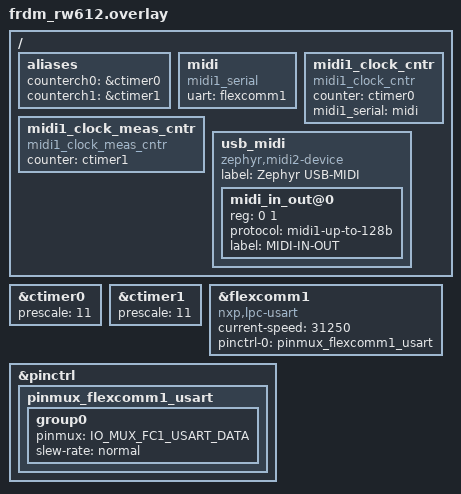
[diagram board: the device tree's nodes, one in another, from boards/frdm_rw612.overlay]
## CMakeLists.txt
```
# SPDX-License-Identifier: Apache-2.0

cmake_minimum_required(VERSION 3.20.0)

find_package(Zephyr REQUIRED HINTS $ENV{ZEPHYR_BASE})
project(chord_display)

target_sources(app PRIVATE 
    src/main.c
    src/chord_detector.c
    src/display.c
)
```

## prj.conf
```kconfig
# SPDX-License-Identifier: Apache-2.0

# MIDI 1.0 Arpeggiator Application
CONFIG_LOG=y
CONFIG_LOG_DEFAULT_LEVEL=1
CONFIG_BOOT_BANNER=y

# Driver support
CONFIG_SERIAL=y
CONFIG_UART_INTERRUPT_DRIVEN=y
CONFIG_MIDI1_SERIAL=y
CONFIG_MIDI1_CLOCK_CNTR=n
CONFIG_MIDI1_HARMONIC=y
CONFIG_COUNTER=n
CONFIG_INPUT=n
CONFIG_INPUT_GPIO_QDEC=n

# Require larger buffers for handling inputs and outputs concurrently
CONFIG_MIDI1_SERIAL_TX_BUF_SIZE=128

# Footprint settings (for the MCXC242) 
#CONFIG_IDLE_STACK_SIZE=256
#CONFIG_ISR_STACK_SIZE=1024
#CONFIG_MAIN_STACK_SIZE=2048
#CONFIG_SYSTEM_WORKQUEUE_STACK_SIZE=2048
```

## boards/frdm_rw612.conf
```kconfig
##########################################################################
#0 @brief FRDM_RW612 additional .conf settings
# @author Jan-Willem Smaal <usenet@gispen.org
##########################################################################

##########################################################################
# Tune these settings to reduce the RAM footprint
##########################################################################
#CONFIG_HEAP_MEM_POOL_SIZE=60000
#CONFIG_MAIN_STACK_SIZE=4096
#CONFIG_ISR_STACK_SIZE=8000

CONFIG_LVGL=y
CONFIG_LV_COLOR_DEPTH_32=y
CONFIG_DISPLAY=y
CONFIG_LVGL=y
#CONFIG_LV_Z_MEM_POOL_SIZE=16384
CONFIG_LV_Z_MEM_POOL_SIZE=32768

CONFIG_DISPLAY=y
CONFIG_INPUT=y


CONFIG_LV_FONT_MONTSERRAT_12=y
CONFIG_LV_FONT_MONTSERRAT_14=y
CONFIG_LV_FONT_MONTSERRAT_16=y
CONFIG_LV_FONT_MONTSERRAT_18=y
CONFIG_LV_FONT_MONTSERRAT_24=y
CONFIG_LV_FONT_MONTSERRAT_48=y
CONFIG_LV_USE_FONT_COMPRESSED=y


# EOF
```

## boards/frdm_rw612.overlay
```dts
/**
 * Device tree overlay created for the FRDM_RW612 development kit
 * adjusted the pinmux so that we can use it for MIDI out and in.
 * @author Jan-Willem Smaal <usenet@gispen.org>
 * @date 20241223
 * updated in 20260206
 * license SPDX-License-Identifier: Apache-2.0
 */
 
 /* Let's make sure both are enabled and act in the same way as the pit0 */
&ctimer0 {
	status = "okay";
	/* Divide 260 MHz by 4 → 24 MHz timer */
	prescale = <11>;
};
&ctimer1 {
	status = "okay";
	/* Divide 260 MHz by 4 → 24 MHz timer */
	prescale = <11>;
};

/* 
 * Configured with the MIDI BAUD rate of 31250 
 * This is the USART on the MIDI arduino shield. 
 * GPIO 8 and 9. 
 */
&flexcomm1 {
	compatible = "nxp,lpc-usart";
	status = "okay";
	current-speed = <31250>;
	pinctrl-0 = <&pinmux_flexcomm1_usart>;
	pinctrl-names = "default";
};

/* 
 * We want to set flexcomm1 to USART instead of the default. 
 * this is why we need to set the pinmux here. 
 */
&pinctrl {
	pinmux_flexcomm1_usart: pinmux_flexcomm1_usart {
		group0 {
			pinmux = <IO_MUX_FC1_USART_DATA>;
			slew-rate = "normal";
		};
	};
};

/ {
	aliases {
		counterch0 = &ctimer0;
		counterch1 = &ctimer1;
	};
	/* MIDI1.0 serial USART driver, set the uart baud to 31250. */
	midi: midi {
		status = "okay";
		compatible = "midi1_serial";
		uart = <&flexcomm1>;
	};
	/* MIDI1.0 clock generator for SERIAL MIDI1.0 */
	midi1_clock_cntr: midi1_clock_cntr {
		status = "okay";
		compatible = "midi1_clock_cntr";
		counter = <&ctimer0>;
		midi1_serial = <&midi>;
	};
	/* MIDI1.0 clock measurement system using the Zephyr timer */
	midi1_clock_meas_cntr: midi1_clock_meas_cntr {
		status = "okay";
		compatible = "midi1_clock_meas_cntr";
		counter = <&ctimer1>;
	};
	/* Zephyr USB MIDI2.0 driver */ 
	usb_midi: usb_midi {
		compatible = "zephyr,midi2-device";
		status = "okay";
		#address-cells = <1>;
		#size-cells = <1>;
		label = "Zephyr USB-MIDI";

		midi_in_out@0 {
			reg = <0 1>;
			protocol = "midi1-up-to-128b";
			label = "MIDI-IN-OUT";
		};
	};
};

/* EOF */
```

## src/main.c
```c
/*
 * SPDX-License-Identifier: Apache-2.0
 */

 /*  
  * This program analyses incoming MIDI notes 
  * and displays the chord on a display. 
  * 
  * @author Jan-Willem Smaal <usenet@gispen.org>
  * @file main.c
  * @date 20260504
  */

#include <zephyr/kernel.h>
#include <zephyr/device.h>
#include <zephyr/logging/log.h>
#include <zephyr/drivers/midi/midi1_serial.h>
#include "chord_detector.h"
#include "display.h"

LOG_MODULE_REGISTER(main, LOG_LEVEL_INF);

int main(void)
{
	LOG_INF("Harmonic Chord Detection Sample Started");
	const struct device *midi_dev = DEVICE_DT_GET(DT_NODELABEL(midi));
	if (!device_is_ready(midi_dev)) {
		LOG_ERR("MIDI device not ready");
		return -ENODEV;
	}
	const struct midi1_serial_api *mid = midi_dev->api; 

	chord_detector_init(midi_dev);

	/* Register callbacks from the detector module */
	mid->register_callbacks(midi_dev, 
		(struct midi1_serial_callbacks *)chord_detector_get_callbacks());

	while (1) {
		mid->receiveparser(midi_dev);
		k_yield();
	}

	return 0;
}
```

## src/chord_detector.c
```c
/*
 * SPDX-License-Identifier: Apache-2.0
 * @author Jan-Willem Smaal <usenet@gispen.org>
 * @file chord_detector.c
 * @date 20260504
 */

#include "chord_detector.h"
#include "display.h"
#include <zephyr/logging/log.h>
#include <zephyr/midi1/harmonic.h>
#include <string.h>

LOG_MODULE_REGISTER(chord_detector, LOG_LEVEL_INF);

#define MAX_SIMULTANEOUS_NOTES 16

static bool active_notes[128];
static harm_mask_t history_mask = 0;
static char last_chord_name[64] = "None";

static struct k_work_delayable reset_work;

static void reset_history_handler(struct k_work *work)
{
	history_mask = 0;
	LOG_INF("Note history reset due to silence.");
	update_scale_display("");
}

static void update_chord_detection(void)
{
	uint8_t notes_to_check[MAX_SIMULTANEOUS_NOTES];
	uint8_t count = 0;

	for (uint8_t i = 0; i < 128 && count < MAX_SIMULTANEOUS_NOTES; i++) {
		if (active_notes[i]) {
			notes_to_check[count++] = i;
			history_mask |= (1u << (i % 12));
		}
	}

	if (count == 0) {
		if (strcmp(last_chord_name, "None") != 0) {
			strcpy(last_chord_name, "None");
			LOG_INF("Detected: %s", last_chord_name);
			update_chord_display(last_chord_name, strlen(last_chord_name));
		}
		/* Schedule reset after 3 seconds of silence */
		k_work_reschedule(&reset_work, K_MSEC(3000));
		return;
	}

	/* Cancel reset timer if notes are playing */
	k_work_cancel_delayable(&reset_work);

	char current_chord[64];
	harm_recognize_chord_from_notes(notes_to_check, count, current_chord,
					sizeof(current_chord));

	if (strcmp(current_chord, last_chord_name) != 0) {
		strcpy(last_chord_name, current_chord);
		LOG_INF("Detected Chord: %s", last_chord_name);
		update_chord_display(last_chord_name, strlen(last_chord_name));

		/* Also perform scale detection on history */
		struct harm_scale_result results[3];
		int found = harm_recognize_scale(history_mask, results, 3);
		if (found > 0) {
			char scale_buf[256] = "Likely Scales:\n";
			LOG_INF("Likely Scales:");
			for (int i = 0; i < found; i++) {
				char line[64];
				snprintf(line, sizeof(line), "- %s %s (%d%%)\n",
					 harm_get_note_name(results[i].root, true), results[i].name,
					 results[i].score);
				strcat(scale_buf, line);
				LOG_INF("  - %s %s (%d%%)",
					harm_get_note_name(results[i].root, true), results[i].name,
					results[i].score);
			}
			update_scale_display(scale_buf);
		}
	}
}

static void note_on_cb(uint8_t channel, uint8_t note, uint8_t velocity)
{
	if (velocity > 0) {
		active_notes[note] = true;
	} else {
		active_notes[note] = false;
	}
	update_chord_detection();
}

static void note_off_cb(uint8_t channel, uint8_t note, uint8_t velocity)
{
	active_notes[note] = false;
	update_chord_detection();
}

static const struct midi1_serial_callbacks detector_callbacks = {
	.note_on = note_on_cb,
	.note_off = note_off_cb,
};

int chord_detector_init(const struct device *dev)
{
	memset(active_notes, 0, sizeof(active_notes));
	k_work_init_delayable(&reset_work, reset_history_handler);
	return 0;
}

const struct midi1_serial_callbacks *chord_detector_get_callbacks(void)
{
	return &detector_callbacks;
}

const char *chord_detector_get_last_name(void)
{
	return last_chord_name;
}
```

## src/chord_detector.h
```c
/*
 * SPDX-License-Identifier: Apache-2.0
 * @author Jan-Willem Smaal <usenet@gispen.org>
 * @file chord_detector.h
 * @date 20260504
 */

#ifndef CHORD_DETECTOR_H_
#define CHORD_DETECTOR_H_

#include <zephyr/kernel.h>
#include <zephyr/drivers/midi/midi1_serial.h>

/**
 * @brief Initialize the chord detector.
 * 
 * @param dev The MIDI device to listen on.
 * @return 0 on success, negative error code otherwise.
 */
int chord_detector_init(const struct device *dev);

/**
 * @brief Get the registered MIDI callbacks for the chord detector.
 * 
 * @return Pointer to the callbacks structure.
 */
const struct midi1_serial_callbacks *chord_detector_get_callbacks(void);

/**
 * @brief Get the last recognized chord name.
 * 
 * @return String containing the chord name.
 */
const char *chord_detector_get_last_name(void);

#endif /* CHORD_DETECTOR_H_ */
```

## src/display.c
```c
/*
 * SPDX-License-Identifier: Apache-2.0
 */

/*
 * @author Jan-Willem Smaal <usenet@gispen.org>
 * @file display.c
 * @date 20260504
 */
#include "display.h"

LOG_MODULE_REGISTER(display, CONFIG_LOG_DEFAULT_LEVEL);
/*
 *  GLOBALS
 */
static lv_obj_t *chord_label;
static lv_obj_t *scale_label;
static struct k_mutex g_model_lock;
static char display_chord_name[64];
static char display_scale_info[256];
static bool display_needs_update;
static bool scale_needs_update;

static void init_display(void)
{
	k_mutex_init(&g_model_lock);
	display_needs_update = false;
	scale_needs_update = false;

	/* Screen background (solid black, no transparency) */
	lv_obj_set_style_bg_color(lv_screen_active(), lv_color_black(), LV_PART_MAIN);
	lv_obj_set_style_bg_opa(lv_screen_active(), LV_OPA_COVER, LV_PART_MAIN);

	/* Chord label: Large font */
	chord_label = lv_label_create(lv_screen_active());
	lv_obj_set_style_text_color(chord_label, lv_color_white(), LV_PART_MAIN);
	lv_obj_set_style_text_font(chord_label, &lv_font_montserrat_48, LV_PART_MAIN);
	lv_label_set_text(chord_label, "Chord Display");
	lv_obj_set_width(chord_label, lv_pct(95));
	lv_obj_set_style_text_align(chord_label, LV_TEXT_ALIGN_CENTER, 0);
	lv_label_set_long_mode(chord_label, LV_LABEL_LONG_WRAP);
	lv_obj_align(chord_label, LV_ALIGN_CENTER, 0, -40);

	/* Scale label: Small font (16) */
	scale_label = lv_label_create(lv_screen_active());
	lv_obj_set_style_text_color(scale_label, lv_color_hex(0xAAFFAA), LV_PART_MAIN);
	lv_obj_set_style_text_font(scale_label, &lv_font_montserrat_18, LV_PART_MAIN);
	lv_label_set_text(scale_label, "");
	lv_obj_set_width(scale_label, lv_pct(95));
	lv_obj_set_style_text_align(scale_label, LV_TEXT_ALIGN_CENTER, 0);
	lv_label_set_long_mode(scale_label, LV_LABEL_LONG_WRAP);
	lv_obj_align(scale_label, LV_ALIGN_CENTER, 0, 60);

	LOG_INF("init done");
}

void update_chord_display(char *buf, uint8_t len)
{
	k_mutex_lock(&g_model_lock, K_FOREVER);
	snprintf(display_chord_name, sizeof(display_chord_name), "%s", buf);
	display_needs_update = true;
	k_mutex_unlock(&g_model_lock);
}

void update_scale_display(const char *buf)
{
	k_mutex_lock(&g_model_lock, K_FOREVER);
	snprintf(display_scale_info, sizeof(display_scale_info), "%s", buf);
	scale_needs_update = true;
	k_mutex_unlock(&g_model_lock);
}

void lvgl_thread(void)
{
	LOG_INF("Starting LVGL thread");

	const struct device *display_dev;

	display_dev = DEVICE_DT_GET(DT_CHOSEN(zephyr_display));
	if (!device_is_ready(display_dev)) {
		LOG_ERR("Device not ready, aborting test");
		return;
	}

	init_display();
	LOG_INF("Starting LVGL loop");
	uint32_t sleep_ms = 0;
	while (1) {
		k_mutex_lock(&g_model_lock, K_FOREVER);
		if (display_needs_update) {
			lv_label_set_text(chord_label, display_chord_name);
			display_needs_update = false;
		}
		if (scale_needs_update) {
			lv_label_set_text(scale_label, display_scale_info);
			scale_needs_update = false;
		}
		k_mutex_unlock(&g_model_lock);

		sleep_ms = lv_timer_handler();
		k_msleep(sleep_ms);
	}
	return;
}

/* For LVGL had to increase the stack size */
K_THREAD_DEFINE(lvgl_thread_tid, 8192, lvgl_thread, NULL, NULL, NULL, 5, 0, 0);

/* EOF */
```

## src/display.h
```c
/*
 * SPDX-License-Identifier: Apache-2.0
 */

/*
 * @author Jan-Willem Smaal <usenet@gispen.org>
 * @file display.c
 * @date 20260504
 */
#ifndef DISPLAY_H
#define DISPLAY_H

#include <zephyr/logging/log.h>
#include <string.h>
#include <lvgl.h>

void update_chord_display(char *buf, uint8_t len);
void update_scale_display(const char *buf);

#endif
/* EOF */
```
